# YTM32B1LE1 register map
Vendor: YTMicro; File version: 1.0
CPU: CM0PLUS r0p1, little endian, MPU, FPU, 2 interrupt priority bits
Registers are 32-bit, read-write, reset 0x0 unless marked. A register's access mark holds for its fields unless they carry their own. Offsets are from the block's base; [hi:lo] are bit positions; {n}, {i} and the like mark numbered series.

## PCTRLA — PORT Control
Base 0x40049000; register names take the prefix PCTRLA_
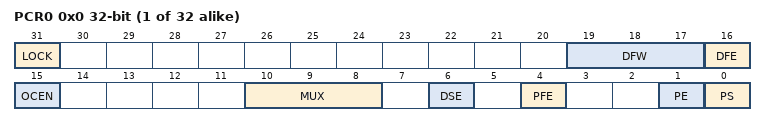
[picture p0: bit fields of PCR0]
{0x0+4i} PCR{i} (i=0..31) — Port control register
  [31] LOCK — Lock Enable configuration for digital pin muxing.
    0=Lock disable; 1=Lock enable, PCR's other bits and related GPIO's output register(PDOR,PSOR,PCOR,PTOR,POER) will be locked until write 0 to this bit
  [19:17] DFW — The digital filter configuration is valid in all digital pin muxing modes. Glitches that are longer than this register setting will pass through the digital filter, and glitches that are equal to or less than this register setting are filtered. Changing the filter length must be done only after all filters are disabled.
  [16] DFE
  [15] OCEN
    0=Output compare disable.The input of digital filter is ind; 1=Output compare enable.The input of digital filter is switched to the xor result of do and ind.As shown in \hyperref[output-compare-diagram]{ " output compare diagram " }
  [10:8] MUX — Not all pin muxing slots are implemented. Unimplemented pin muxing slots are reserved. Please refer to pinmux table for detailed peripheral functions. The corresponding pin is configured in the following pin muxing slot as follows:
    0=Alternative 0, Analog function, digital function is disabled; 1=Alternative 1, GPIO function; {v}=Alternative {v} (v=2..7)
  [6] DSE — Drive strength configuration for digital pin muxing.
    0=Low drive strength, if the pin is configured as a digital output; 1=High drive strength, if the pin is configured as a digital output
  [4] PFE — Passive filter configuration for digital pin muxing.
    0=Passive input filter is disabled; 1=Passive input filter is enabled, if the pin is configured as a digital input
  [1] PE — Pull configuration for digital pin muxing.
    0=Internal pullup or pulldown resistor is not enabled; 1=Internal pullup or pulldown resistor is enabled
  [0] PS — Pull configuration for digital pin muxing.
    0=Internal pulldown resistor is enabled, if PE field is set; 1=Internal pullup resistor is enabled, if PE field is set

## PCTRLB — PORT Control
Base 0x4004A000; register names take the prefix PCTRLB_
Registers as PCTRLA.

## PCTRLC — PORT Control
Base 0x4004B000; register names take the prefix PCTRLC_
Registers as PCTRLA.

## PCTRLD — PORT Control
Base 0x4004C000; register names take the prefix PCTRLD_
Registers as PCTRLA.

## PCTRLE — PORT Control
Base 0x4004D000; register names take the prefix PCTRLE_
Registers as PCTRLA.

## TMU — Trigger Multiplexer Module
Base 0x40063000; register names take the prefix TMU_
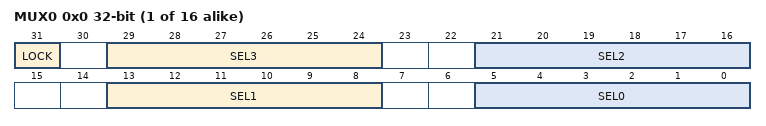
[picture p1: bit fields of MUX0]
{0x0+4i} MUX{i} (i=0..15)
  [31] LOCK — Lock the MUX select for peripheral trigger input, this bit can be only clear by reset.
  [8n+5:8n] SEL{n} (n=0..3) — This read/write bit field is used to configure the MUX select for peripheral trigger input.

## SCU — System Clock Unit of Microcontroller
Base 0x40064000; register names take the prefix SCU_
0x00 CLKS — The register contains clock select bits.
  [1:0] CLKSRCSEL — System Clock Source selection bits.
    0=Select FIRC as system clock source; 2=Select FXOSC as system clock source; 3=Select SIRC as system clock source
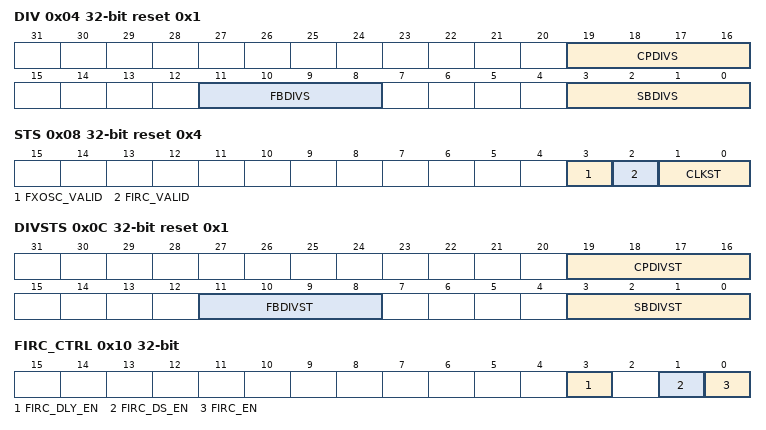
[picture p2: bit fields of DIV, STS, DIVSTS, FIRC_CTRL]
0x04 DIV reset 0x1 — System Clock Divider
  [all] fields
    {v}=Divide by {v+1} (v=0..15)
  [19:16] CPDIVS — Core Platform Clock Divider Value
  [11:8] FBDIVS — Fast Bus Clock Divider Value
  [3:0] SBDIVS — Slow Bus Clock Divider Value
0x08 STS ro reset 0x4 — System Clock Unit Status register
  [3] FXOSC_VALID rw — Indicates FXOSC Clock is valid.
    0=FXOSC Clock invalid; 1=FXOSC Clock valid
  [2] FIRC_VALID rw — Indicates FIRC Clock is valid.
    0=FIRC Clock invalid; 1=FIRC Clock valid
  [1:0] CLKST rw — Indicats System Clock Source Selection status.
    0=FIRC is selected as system clock source; 2=FXOSC is selected as system clock source; 3=SIRC is selected as system clock source
0x0C DIVSTS ro reset 0x1 — System Clock Unit clock divider status
  [all] fields
    {v}=Divide by {v+1} (v=0..15)
  [19:16] CPDIVST rw — Core Platform Clock Divider Value
  [11:8] FBDIVST rw — Fast Bus Clock Divider Value
  [3:0] SBDIVST rw — Slow Bus Clock Divider Value
0x10 FIRC_CTRL — FIRC control register
  [3] FIRC_DLY_EN — Delay FIRC clock out.
    0=Disable FIRC clock out delay; 1=Enable FIRC clock out delay
  [1] FIRC_DS_EN — Enable FIRC when chip enters Deepsleep mode.
    0=Disable FIRC when chip enters Deepsleep mode; 1=Enable FIRC when chip enters Deepsleep mode
  [0] FIRC_EN — Enable FIRC regardless it is selected as system clock source.
    0=Disable FIRC if it is not selected as system clock source; 1=Enable FIRC regardless it is selected as system clock or not
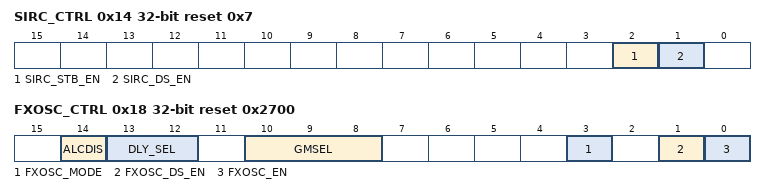
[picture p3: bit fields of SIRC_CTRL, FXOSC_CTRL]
0x14 SIRC_CTRL reset 0x7 — SIRC control register
  [2] SIRC_STB_EN — Enable SIRC when chip enters Standby mode.
    0=Disable SIRC when chip enters Standby mode; 1=Enable SIRC when chip enters Standby mode
  [1] SIRC_DS_EN — Enable SIRC when chip enters Deepsleep mode.
    0=Disable SIRC when chip enters Deepsleep mode; 1=Enable SIRC when chip enters Deepsleep mode
0x18 FXOSC_CTRL reset 0x2700 — FXOSC control register
  [14] ALCDIS — This bit should not be changed when FXOSC_VALID is high
  [13:12] DLY_SEL — FXOSC clock output delay select.
    0=4096 cycles; 1=8192 cycles; 2=16384 cycles (default); 3=32768 cycles
  [10:8] GMSEL — FXOSC Gain Select for different oscillators
    1=used for 4MHz-6MHz oscillator; 2=used for 6MHz-8MHz oscillator; 3=used for 8MHz-12MHz oscillator; 5=used for 12MHz-20MHz oscillator; 6=used for 20MHz-32MHz oscillator; 7=used for 32MHz-40MHz oscillator
  [3] FXOSC_MODE — Select FXOSC oscillator mode or bypass mode
    0=FXOSC bypass mode; 1=FXOSC oscillator mode
  [1] FXOSC_DS_EN — Enable FXOSC when chip enters Deepsleep mode.
    0=Disable FXOSC when chip enters Deepsleep mode; 1=Enable FXOSC when chip enters Deepsleep mode
  [0] FXOSC_EN — Enable Fast crystal osc regardless it is selected as system clock source.
    0=Disable FXOSC if it is not selected as system clock source; 1=Enable FXOSC regardless it is selected as system clock or not
